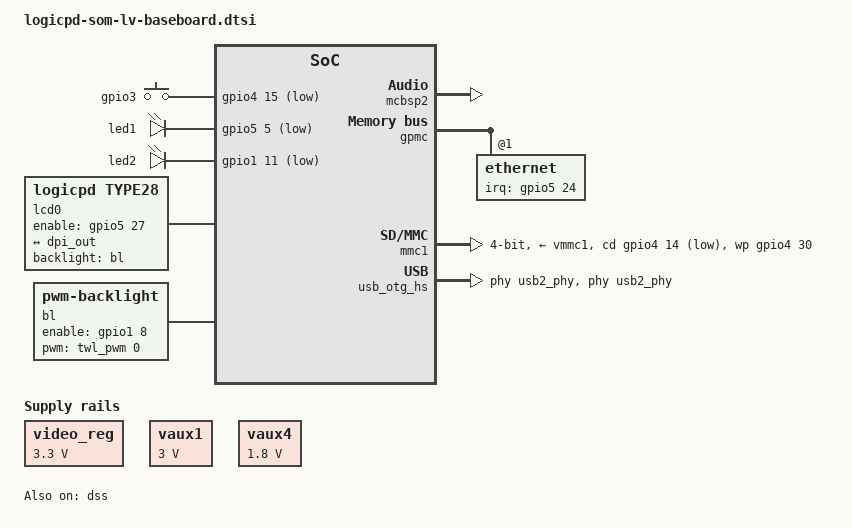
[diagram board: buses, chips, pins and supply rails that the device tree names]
/ {
	gpio_keys {
		compatible = "gpio-keys";
		pinctrl-names = "default";
		pinctrl-0 = <&gpio_key_pins>;
		sysboot2 {
			label = "gpio3";
			gpios = <&gpio4 15 GPIO_ACTIVE_LOW>;	 
			linux,code = <BTN_0>;
			wakeup-source;
		};
	};
	sound {
		compatible = "ti,omap-twl4030";
		ti,model = "omap3logic";
		ti,mcbsp = <&mcbsp2>;
	};
	leds {
		compatible = "gpio-leds";
		pinctrl-names = "default";
		pinctrl-0 = <&led_pins &led_pins_wkup>;
		led1 {
			label = "led1";
			gpios = <&gpio5 5 GPIO_ACTIVE_LOW>;	 
			linux,default-trigger = "cpu0";
		};
		led2 {
			label = "led2";
			gpios = <&gpio1 11 GPIO_ACTIVE_LOW>;	 
			linux,default-trigger = "none";
		};
	};
};
&vaux1 {
	regulator-min-microvolt = <3000000>;
	regulator-max-microvolt = <3000000>;
};
&vaux4 {
	regulator-min-microvolt = <1800000>;
	regulator-max-microvolt = <1800000>;
};
&mcbsp2 {
	status = "okay";
	pinctrl-names = "default";
	pinctrl-0 = <&mcbsp2_pins>;
};
&charger {
	ti,bb-uvolt = <3200000>;
	ti,bb-uamp = <150>;
};
&gpmc {
	ranges = <0 0 0x30000000 0x1000000	 
		  1 0 0x2c000000 0x1000000	 
		  2 0 0x10000000 0x2000000>;     
	ethernet@gpmc {
		pinctrl-names = "default";
		pinctrl-0 = <&lan9221_pins>;
		interrupt-parent = <&gpio5>;
		interrupts = <24 IRQ_TYPE_LEVEL_LOW>;		 
		reg = <1 0 0xff>;
	};
};
&vpll2 {
	regulator-always-on;
};
&dss {
	status = "okay";
	vdds_dsi-supply = <&vpll2>;
	vdda_video-supply = <&video_reg>;
	pinctrl-names = "default";
	pinctrl-0 = <&dss_dpi_pins1>;
	port {
		dpi_out: endpoint {
			remote-endpoint = <&lcd_in>;
			data-lines = <16>;
		};
	};
};
/ {
	aliases {
		display0 = &lcd0;
	};
	video_reg: video_reg {
		compatible = "regulator-fixed";
		regulator-name = "fixed-supply";
		regulator-min-microvolt = <3300000>;
		regulator-max-microvolt = <3300000>;
	};
	lcd0: display {
		compatible = "logicpd,type28";
		pinctrl-names = "default";
		pinctrl-0 = <&lcd_enable_pin>;
		backlight = <&bl>;
		enable-gpios = <&gpio5 27 GPIO_ACTIVE_HIGH>;
		port {
			lcd_in: endpoint {
				remote-endpoint = <&dpi_out>;
			};
		};
	};
	bl: backlight {
		compatible = "pwm-backlight";
		pinctrl-names = "default";
		pinctrl-0 = <&backlight_pins>;
		pwms = <&twl_pwm 0 5000000>;
		brightness-levels = <0 10 20 30 40 50 60 70 80 90 100>;
		default-brightness-level = <7>;
		enable-gpios = <&gpio1 8 GPIO_ACTIVE_HIGH>;  
	};
};
&mmc1 {
	interrupts-extended = <&intc 83 &omap3_pmx_core 0x11a>;
	pinctrl-names = "default";
	pinctrl-0 = <&mmc1_pins>;
	wp-gpios = <&gpio4 30 GPIO_ACTIVE_HIGH>;		 
	cd-gpios = <&gpio4 14 GPIO_ACTIVE_LOW>;			 
	vmmc-supply = <&vmmc1>;
	bus-width = <4>;
	cap-power-off-card;
};
&omap3_pmx_core {
	gpio_key_pins: gpio-key-pins {
		pinctrl-single,pins = <
			OMAP3_CORE1_IOPAD(0x212e, PIN_INPUT_PULLUP | MUX_MODE4)	 
		>;
	};
	led_pins: led-pins {
		pinctrl-single,pins = <
			OMAP3_CORE1_IOPAD(0x215e, PIN_OUTPUT_PULLUP | MUX_MODE4)	 
		>;
	};
	lan9221_pins: lan9221-pins {
		pinctrl-single,pins = <
			OMAP3_CORE1_IOPAD(0x2184, PIN_INPUT_PULLUP | MUX_MODE4)	 
		>;
	};
	mmc1_pins: mmc1-pins {
		pinctrl-single,pins = <
			OMAP3_CORE1_IOPAD(0x2144, PIN_OUTPUT | MUX_MODE0)	 
			OMAP3_CORE1_IOPAD(0x2146, PIN_INPUT | MUX_MODE0)	 
			OMAP3_CORE1_IOPAD(0x2148, PIN_INPUT | MUX_MODE0)	 
			OMAP3_CORE1_IOPAD(0x214a, PIN_INPUT | MUX_MODE0)	 
			OMAP3_CORE1_IOPAD(0x214c, PIN_INPUT | MUX_MODE0)	 
			OMAP3_CORE1_IOPAD(0x214e, PIN_INPUT | MUX_MODE0)	 
			OMAP3_CORE1_IOPAD(0x2132, PIN_INPUT_PULLUP | MUX_MODE4)	 
			OMAP3_CORE1_IOPAD(0x212c, PIN_INPUT_PULLUP | MUX_MODE4)	 
		>;
	};
	lcd_enable_pin: lcd-enable-pins {
		pinctrl-single,pins = <
			OMAP3_CORE1_IOPAD(0x218a, PIN_OUTPUT | PIN_OFF_OUTPUT_LOW | MUX_MODE4)        
		>;
	};
	dss_dpi_pins1: dss-dpi1-pins {
		pinctrl-single,pins = <
			OMAP3_CORE1_IOPAD(0x20d4, PIN_OUTPUT_PULLDOWN | PIN_OFF_OUTPUT_LOW | MUX_MODE0)    
			OMAP3_CORE1_IOPAD(0x20d6, PIN_OUTPUT_PULLDOWN | PIN_OFF_OUTPUT_LOW | MUX_MODE0)    
			OMAP3_CORE1_IOPAD(0x20d8, PIN_OUTPUT_PULLDOWN | PIN_OFF_OUTPUT_LOW | MUX_MODE0)    
			OMAP3_CORE1_IOPAD(0x20da, PIN_OUTPUT_PULLDOWN | PIN_OFF_OUTPUT_LOW | MUX_MODE0)    
			OMAP3_CORE1_IOPAD(0x20dc, PIN_OUTPUT_PULLDOWN | PIN_OFF_OUTPUT_LOW | MUX_MODE0)    
			OMAP3_CORE1_IOPAD(0x20de, PIN_OUTPUT_PULLDOWN | PIN_OFF_OUTPUT_LOW | MUX_MODE0)    
			OMAP3_CORE1_IOPAD(0x20e0, PIN_OUTPUT_PULLDOWN | PIN_OFF_OUTPUT_LOW | MUX_MODE0)    
			OMAP3_CORE1_IOPAD(0x20e2, PIN_OUTPUT_PULLDOWN | PIN_OFF_OUTPUT_LOW | MUX_MODE0)    
			OMAP3_CORE1_IOPAD(0x20e4, PIN_OUTPUT_PULLDOWN | PIN_OFF_OUTPUT_LOW | MUX_MODE0)    
			OMAP3_CORE1_IOPAD(0x20e6, PIN_OUTPUT_PULLDOWN | PIN_OFF_OUTPUT_LOW | MUX_MODE0)    
			OMAP3_CORE1_IOPAD(0x20e8, PIN_OUTPUT_PULLDOWN | PIN_OFF_OUTPUT_LOW | MUX_MODE0)    
			OMAP3_CORE1_IOPAD(0x20ea, PIN_OUTPUT_PULLDOWN | PIN_OFF_OUTPUT_LOW | MUX_MODE0)    
			OMAP3_CORE1_IOPAD(0x20ec, PIN_OUTPUT_PULLDOWN | PIN_OFF_OUTPUT_LOW | MUX_MODE0)    
			OMAP3_CORE1_IOPAD(0x20ee, PIN_OUTPUT_PULLDOWN | PIN_OFF_OUTPUT_LOW | MUX_MODE0)    
			OMAP3_CORE1_IOPAD(0x20f0, PIN_OUTPUT_PULLDOWN | PIN_OFF_OUTPUT_LOW | MUX_MODE0)    
			OMAP3_CORE1_IOPAD(0x20f2, PIN_OUTPUT_PULLDOWN | PIN_OFF_OUTPUT_LOW | MUX_MODE0)    
			OMAP3_CORE1_IOPAD(0x20f4, PIN_OUTPUT_PULLDOWN | PIN_OFF_OUTPUT_LOW | MUX_MODE0)    
			OMAP3_CORE1_IOPAD(0x20f6, PIN_OUTPUT_PULLDOWN | PIN_OFF_OUTPUT_LOW | MUX_MODE0)    
			OMAP3_CORE1_IOPAD(0x20f8, PIN_OUTPUT_PULLDOWN | PIN_OFF_OUTPUT_LOW | MUX_MODE0)    
			OMAP3_CORE1_IOPAD(0x20fa, PIN_OUTPUT_PULLDOWN | PIN_OFF_OUTPUT_LOW | MUX_MODE0)    
		>;
	};
};
&omap3_pmx_wkup {
	led_pins_wkup: led-wkup-pins {
		pinctrl-single,pins = <
			OMAP3_WKUP_IOPAD(0x2a24, PIN_OUTPUT_PULLUP | MUX_MODE4)	 
		>;
	};
	backlight_pins: backlight-pins {
		pinctrl-single,pins = <
			OMAP3_WKUP_IOPAD(0x2a16, PIN_OUTPUT | PIN_OFF_OUTPUT_LOW | MUX_MODE4)        
		>;
	};
};
&uart1 {
	interrupts-extended = <&intc 72 &omap3_pmx_core OMAP3_UART1_RX>;
};
&usb_otg_hs {
	pinctrl-names = "default";
	pinctrl-0 = <&hsusb_otg_pins>;
	interface-type = <0>;
	usb-phy = <&usb2_phy>;
	phys = <&usb2_phy>;
	phy-names = "usb2-phy";
	mode = <3>;
	power = <50>;
};
